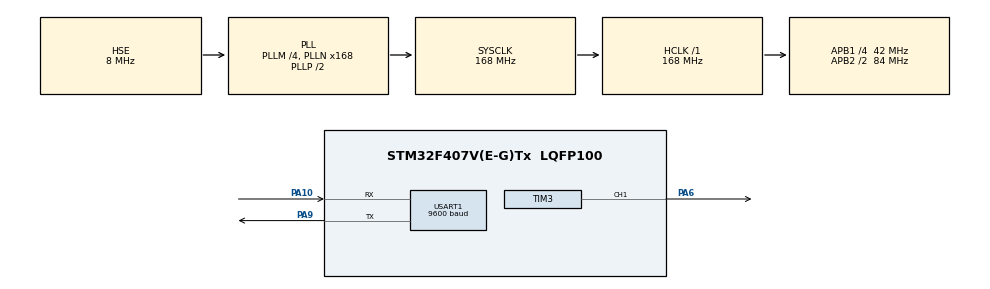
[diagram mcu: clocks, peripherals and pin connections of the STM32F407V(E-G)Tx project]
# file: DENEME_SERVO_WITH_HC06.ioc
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Mcu.Family=STM32F4
Mcu.Name=STM32F407V(E-G)Tx
Mcu.Package=LQFP100
NVIC.PriorityGroup=NVIC_PRIORITYGROUP_4
PA10.Mode=Asynchronous
PA10.Signal=USART1_RX
PA6.Signal=S_TIM3_CH1
PA9.Mode=Asynchronous
PA9.Signal=USART1_TX
PH0-OSC_IN.Mode=HSE-External-Oscillator
PH0-OSC_IN.Signal=RCC_OSC_IN
PH1-OSC_OUT.Mode=HSE-External-Oscillator
PH1-OSC_OUT.Signal=RCC_OSC_OUT
ProjectManager.HeapSize=0x200
ProjectManager.StackSize=0x400
ProjectManager.TargetToolchain=STM32CubeIDE
RCC.48MHZClocksFreq_Value=84000000
RCC.AHBFreq_Value=168000000
RCC.APB1CLKDivider=RCC_HCLK_DIV4
RCC.APB1Freq_Value=42000000
RCC.APB1TimFreq_Value=84000000
RCC.APB2CLKDivider=RCC_HCLK_DIV2
RCC.APB2Freq_Value=84000000
RCC.APB2TimFreq_Value=168000000
RCC.CortexFreq_Value=168000000
RCC.HCLKFreq_Value=168000000
RCC.HSE_VALUE=8000000
RCC.HSI_VALUE=16000000
RCC.LSE_VALUE=32768
RCC.PLLM=4
RCC.PLLN=168
RCC.PLLSourceVirtual=RCC_PLLSOURCE_HSE
RCC.SYSCLKFreq_VALUE=168000000
RCC.SYSCLKSource=RCC_SYSCLKSOURCE_PLLCLK
RCC.VCOOutputFreq_Value=336000000
SH.S_TIM3_CH1.0=TIM3_CH1,PWM Generation1 CH1
TIM3.Channel-PWM\ Generation1\ CH1=TIM_CHANNEL_1
TIM3.Period=1999
TIM3.Prescaler=83
USART1.BaudRate=9600
USART1.VirtualMode=VM_ASYNC
VP_TIM3_VS_ClockSourceINT.Mode=Internal
board=custom

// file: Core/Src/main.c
/* USER CODE BEGIN Header */
/**
  ******************************************************************************
  * @file           : main.c
  * @brief          : Main program body
  ******************************************************************************
  * @attention
  *
  * <h2><center>&copy; Copyright (c) 2021 STMicroelectronics.
  * All rights reserved.</center></h2>
  *
  * This software component is licensed by ST under BSD 3-Clause license,
  * the "License"; You may not use this file except in compliance with the
  * License. You may obtain a copy of the License at:
  *                        opensource.org/licenses/BSD-3-Clause
  *
  ******************************************************************************
  */
/* USER CODE END Header */
#include "main.h"

#include <stdio.h>

TIM_HandleTypeDef htim3;

UART_HandleTypeDef huart1;

/* USER CODE BEGIN PV */
char rx_data[3]  ;
uint16_t counter = 500 ;
/* USER CODE END PV */

void SystemClock_Config(void);
static void MX_GPIO_Init(void);
static void MX_USART1_UART_Init(void);
static void MX_TIM3_Init(void);

/* USER CODE BEGIN 0 */
void control()
{
	  if (rx_data[0] == '+' )
	  {
		  if (counter <= 2400)
			  counter += 100 ;

	  }
	  if (rx_data[0] == '-')
	  {
		  if (counter >= 600) counter -= 100 ;
	  }

	  rx_data[0] = '\0' ; // Clear rx_data variable

}
/* USER CODE END 0 */

int main(void)
{
  /* USER CODE BEGIN 1 */
  fprintf(stderr, "Standard error message.\n");
  fprintf(stdout, "Standard error message.\n");
  /* USER CODE END 1 */

  /* MCU Configuration--------------------------------------------------------*/

  /* Reset of all peripherals, Initializes the Flash interface and the Systick. */
  HAL_Init();

  /* Configure the system clock */
  SystemClock_Config();

  /* Initialize all configured peripherals */
  MX_GPIO_Init();
  MX_USART1_UART_Init();
  MX_TIM3_Init();
  /* USER CODE BEGIN 2 */
  HAL_TIM_PWM_Start(&htim3, TIM_CHANNEL_1); // Start Timer for PWM
  __HAL_TIM_SET_COMPARE(&htim3,TIM_CHANNEL_1,counter);
  /* USER CODE END 2 */

  /* Infinite loop */
  while (1)
  {

    /* USER CODE BEGIN 3 */

	  // Link of project video -------->  https://drive.google.com/file/d/1p5s7OUA4AjGCqYyCosQESfKeiAxB_qvp/view?usp=sharing

	  control();

	  HAL_UART_Receive(&huart1, (uint8_t *)rx_data, 3, 100);

	  __HAL_TIM_SET_COMPARE(&htim3,TIM_CHANNEL_1,counter);

  }
  /* USER CODE END 3 */
}

void SystemClock_Config(void)
{
  RCC_OscInitTypeDef RCC_OscInitStruct = {0};
  RCC_ClkInitTypeDef RCC_ClkInitStruct = {0};

  /** Configure the main internal regulator output voltage
  */
  __HAL_RCC_PWR_CLK_ENABLE();
  __HAL_PWR_VOLTAGESCALING_CONFIG(PWR_REGULATOR_VOLTAGE_SCALE1);
  /** Initializes the RCC Oscillators according to the specified parameters
  * in the RCC_OscInitTypeDef structure.
  */
  RCC_OscInitStruct.OscillatorType = RCC_OSCILLATORTYPE_HSE;
  RCC_OscInitStruct.HSEState = RCC_HSE_ON;
  RCC_OscInitStruct.PLL.PLLState = RCC_PLL_ON;
  RCC_OscInitStruct.PLL.PLLSource = RCC_PLLSOURCE_HSE;
  RCC_OscInitStruct.PLL.PLLM = 4;
  RCC_OscInitStruct.PLL.PLLN = 168;
  RCC_OscInitStruct.PLL.PLLP = RCC_PLLP_DIV2;
  RCC_OscInitStruct.PLL.PLLQ = 4;
  if (HAL_RCC_OscConfig(&RCC_OscInitStruct) != HAL_OK)
  {
    Error_Handler();
  }
  /** Initializes the CPU, AHB and APB buses clocks
  */
  RCC_ClkInitStruct.ClockType = RCC_CLOCKTYPE_HCLK|RCC_CLOCKTYPE_SYSCLK
                              |RCC_CLOCKTYPE_PCLK1|RCC_CLOCKTYPE_PCLK2;
  RCC_ClkInitStruct.SYSCLKSource = RCC_SYSCLKSOURCE_PLLCLK;
  RCC_ClkInitStruct.AHBCLKDivider = RCC_SYSCLK_DIV1;
  RCC_ClkInitStruct.APB1CLKDivider = RCC_HCLK_DIV4;
  RCC_ClkInitStruct.APB2CLKDivider = RCC_HCLK_DIV2;

  if (HAL_RCC_ClockConfig(&RCC_ClkInitStruct, FLASH_LATENCY_5) != HAL_OK)
  {
    Error_Handler();
  }
}

static void MX_TIM3_Init(void)
{

  TIM_ClockConfigTypeDef sClockSourceConfig = {0};
  TIM_MasterConfigTypeDef sMasterConfig = {0};
  TIM_OC_InitTypeDef sConfigOC = {0};

  htim3.Instance = TIM3;
  htim3.Init.Prescaler = 83;
  htim3.Init.CounterMode = TIM_COUNTERMODE_UP;
  htim3.Init.Period = 1999;
  htim3.Init.ClockDivision = TIM_CLOCKDIVISION_DIV1;
  htim3.Init.AutoReloadPreload = TIM_AUTORELOAD_PRELOAD_DISABLE;
  if (HAL_TIM_Base_Init(&htim3) != HAL_OK)
  {
    Error_Handler();
  }
  sClockSourceConfig.ClockSource = TIM_CLOCKSOURCE_INTERNAL;
  if (HAL_TIM_ConfigClockSource(&htim3, &sClockSourceConfig) != HAL_OK)
  {
    Error_Handler();
  }
  if (HAL_TIM_PWM_Init(&htim3) != HAL_OK)
  {
    Error_Handler();
  }
  sMasterConfig.MasterOutputTrigger = TIM_TRGO_RESET;
  sMasterConfig.MasterSlaveMode = TIM_MASTERSLAVEMODE_DISABLE;
  if (HAL_TIMEx_MasterConfigSynchronization(&htim3, &sMasterConfig) != HAL_OK)
  {
    Error_Handler();
  }
  sConfigOC.OCMode = TIM_OCMODE_PWM1;
  sConfigOC.Pulse = 0;
  sConfigOC.OCPolarity = TIM_OCPOLARITY_HIGH;
  sConfigOC.OCFastMode = TIM_OCFAST_DISABLE;
  if (HAL_TIM_PWM_ConfigChannel(&htim3, &sConfigOC, TIM_CHANNEL_1) != HAL_OK)
  {
    Error_Handler();
  }
  HAL_TIM_MspPostInit(&htim3);

}

static void MX_USART1_UART_Init(void)
{

  huart1.Instance = USART1;
  huart1.Init.BaudRate = 9600;
  huart1.Init.WordLength = UART_WORDLENGTH_8B;
  huart1.Init.StopBits = UART_STOPBITS_1;
  huart1.Init.Parity = UART_PARITY_NONE;
  huart1.Init.Mode = UART_MODE_TX_RX;
  huart1.Init.HwFlowCtl = UART_HWCONTROL_NONE;
  huart1.Init.OverSampling = UART_OVERSAMPLING_16;
  if (HAL_UART_Init(&huart1) != HAL_OK)
  {
    Error_Handler();
  }

}

static void MX_GPIO_Init(void)
{

  /* GPIO Ports Clock Enable */
  __HAL_RCC_GPIOH_CLK_ENABLE();
  __HAL_RCC_GPIOA_CLK_ENABLE();

}

void Error_Handler(void)
{
  __disable_irq();
  while (1)
  {
  }
}

/************************ (C) COPYRIGHT STMicroelectronics *****END OF FILE****/
